VERSION "created by canmatrix"

NS_ :

BS_:

BU_: User ADM_PC_LL25 ADM_PC_BC25 ADM_PC_BP25 ADM_PC_BI25

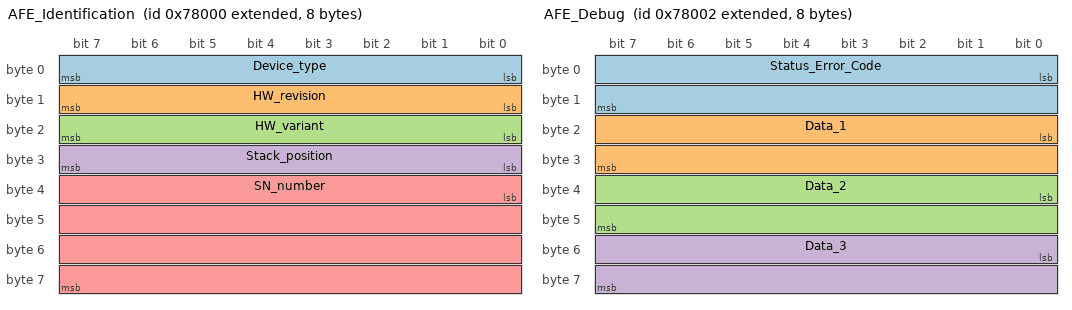
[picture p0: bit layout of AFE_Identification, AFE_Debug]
BO_ 2147975168 AFE_Identification: 8 ADM_PC_BP25
 SG_ Device_type : 0|8@1+ (1,0) [0|255] "" Vector__XXX
 SG_ HW_revision : 8|8@1+ (1,0) [0|255] "" Vector__XXX
 SG_ HW_variant : 16|8@1+ (1,0) [0|255] "" Vector__XXX
 SG_ Stack_position : 24|8@1+ (1,0) [0|255] "" Vector__XXX
 SG_ SN_number : 32|32@1+ (1,0) [0|4294967295] "" Vector__XXX

BO_ 2147975169 AFE_FwInfo: 8 ADM_PC_BP25
 SG_ FW_info_mux M : 56|8@1+ (1,0) [0|255] "" Vector__XXX
 SG_ FW_revision_0 m0 : 0|8@1+ (1,0) [0|255] "" Vector__XXX
 SG_ FW_revision_1 m0 : 8|8@1+ (1,0) [0|255] "" Vector__XXX
 SG_ FW_revision_2 m0 : 16|8@1+ (1,0) [0|255] "" Vector__XXX
 SG_ FW_revision_3 m0 : 24|8@1+ (1,0) [0|255] "" Vector__XXX
 SG_ FW_revision_4 m0 : 32|8@1+ (1,0) [0|255] "" Vector__XXX
 SG_ FW_revision_5 m0 : 40|8@1+ (1,0) [0|255] "" Vector__XXX
 SG_ FW_revision_6 m0 : 48|8@1+ (1,0) [0|255] "" Vector__XXX
 SG_ FW_revision_7 m1 : 0|8@1+ (1,0) [0|255] "" Vector__XXX
 SG_ FW_revision_8 m1 : 8|8@1+ (1,0) [0|255] "" Vector__XXX
 SG_ FW_revision_9 m1 : 16|8@1+ (1,0) [0|255] "" Vector__XXX
 SG_ FW_revision_10 m1 : 24|8@1+ (1,0) [0|255] "" Vector__XXX
 SG_ FW_revision_11 m1 : 32|8@1+ (1,0) [0|255] "" Vector__XXX
 SG_ FW_revision_12 m1 : 40|8@1+ (1,0) [0|255] "" Vector__XXX
 SG_ FW_revision_13 m1 : 48|8@1+ (1,0) [0|255] "" Vector__XXX
 SG_ FW_datecode_0 m2 : 0|8@1+ (1,0) [0|255] "" Vector__XXX
 SG_ FW_datecode_1 m2 : 8|8@1+ (1,0) [0|255] "" Vector__XXX
 SG_ FW_datecode_2 m2 : 16|8@1+ (1,0) [0|255] "" Vector__XXX
 SG_ FW_datecode_3 m2 : 24|8@1+ (1,0) [0|255] "" Vector__XXX
 SG_ FW_datecode_4 m2 : 32|8@1+ (1,0) [0|255] "" Vector__XXX
 SG_ FW_datecode_5 m2 : 40|8@1+ (1,0) [0|255] "" Vector__XXX
 SG_ FW_datecode_6 m2 : 48|8@1+ (1,0) [0|255] "" Vector__XXX
 SG_ FW_datecode_7 m3 : 0|8@1+ (1,0) [0|255] "" Vector__XXX
 SG_ FW_datecode_8 m3 : 8|8@1+ (1,0) [0|255] "" Vector__XXX
 SG_ FW_datecode_9 m3 : 16|8@1+ (1,0) [0|255] "" Vector__XXX
 SG_ FW_datecode_10 m3 : 24|8@1+ (1,0) [0|255] "" Vector__XXX
 SG_ FW_datecode_11 m3 : 32|8@1+ (1,0) [0|255] "" Vector__XXX
 SG_ FW_datecode_12 m3 : 40|8@1+ (1,0) [0|255] "" Vector__XXX
 SG_ FW_datecode_13 m3 : 48|8@1+ (1,0) [0|255] "" Vector__XXX

BO_ 2147975181 _AFE_Boot_FwInfo: 8 ADM_PC_BP25
 SG_ Boot_FW_info_mux M : 56|8@1+ (1,0) [0|255] "" Vector__XXX
 SG_ FW_revision_0 m0 : 0|8@1+ (1,0) [0|255] "" Vector__XXX
 SG_ FW_revision_1 m0 : 8|8@1+ (1,0) [0|255] "" Vector__XXX
 SG_ FW_revision_2 m0 : 16|8@1+ (1,0) [0|255] "" Vector__XXX
 SG_ FW_revision_3 m0 : 24|8@1+ (1,0) [0|255] "" Vector__XXX
 SG_ FW_revision_4 m0 : 32|8@1+ (1,0) [0|255] "" Vector__XXX
 SG_ FW_revision_5 m0 : 40|8@1+ (1,0) [0|255] "" Vector__XXX
 SG_ FW_revision_6 m0 : 48|8@1+ (1,0) [0|255] "" Vector__XXX
 SG_ FW_revision_7 m1 : 0|8@1+ (1,0) [0|255] "" Vector__XXX
 SG_ FW_revision_8 m1 : 8|8@1+ (1,0) [0|255] "" Vector__XXX
 SG_ FW_revision_9 m1 : 16|8@1+ (1,0) [0|255] "" Vector__XXX
 SG_ FW_revision_10 m1 : 24|8@1+ (1,0) [0|255] "" Vector__XXX
 SG_ FW_revision_11 m1 : 32|8@1+ (1,0) [0|255] "" Vector__XXX
 SG_ FW_revision_12 m1 : 40|8@1+ (1,0) [0|255] "" Vector__XXX
 SG_ FW_revision_13 m1 : 48|8@1+ (1,0) [0|255] "" Vector__XXX
 SG_ FW_datecode_0 m2 : 0|8@1+ (1,0) [0|255] "" Vector__XXX
 SG_ FW_datecode_1 m2 : 8|8@1+ (1,0) [0|255] "" Vector__XXX
 SG_ FW_datecode_2 m2 : 16|8@1+ (1,0) [0|255] "" Vector__XXX
 SG_ FW_datecode_3 m2 : 24|8@1+ (1,0) [0|255] "" Vector__XXX
 SG_ FW_datecode_4 m2 : 32|8@1+ (1,0) [0|255] "" Vector__XXX
 SG_ FW_datecode_5 m2 : 40|8@1+ (1,0) [0|255] "" Vector__XXX
 SG_ FW_datecode_6 m2 : 48|8@1+ (1,0) [0|255] "" Vector__XXX
 SG_ FW_datecode_7 m3 : 0|8@1+ (1,0) [0|255] "" Vector__XXX
 SG_ FW_datecode_8 m3 : 8|8@1+ (1,0) [0|255] "" Vector__XXX
 SG_ FW_datecode_9 m3 : 16|8@1+ (1,0) [0|255] "" Vector__XXX
 SG_ FW_datecode_10 m3 : 24|8@1+ (1,0) [0|255] "" Vector__XXX
 SG_ FW_datecode_11 m3 : 32|8@1+ (1,0) [0|255] "" Vector__XXX
 SG_ FW_datecode_12 m3 : 40|8@1+ (1,0) [0|255] "" Vector__XXX
 SG_ FW_datecode_13 m3 : 48|8@1+ (1,0) [0|255] "" Vector__XXX

BO_ 2147975170 AFE_Debug: 8 ADM_PC_BP25
 SG_ Status_Error_Code : 0|16@1+ (1,0) [0|65535] "" Vector__XXX
 SG_ Data_1 : 16|16@1+ (1,0) [0|65535] "" Vector__XXX
 SG_ Data_2 : 32|16@1+ (1,0) [0|65535] "" Vector__XXX
 SG_ Data_3 : 48|16@1+ (1,0) [0|65535] "" Vector__XXX

BO_ 2147975175 AFE_Status: 8 ADM_PC_BP25
 SG_ Running : 0|1@1+ (1,0) [0|1] "" Vector__XXX
 SG_ PWM : 1|1@1+ (1,0) [0|1] "" Vector__XXX
 SG_ Current_dc_loop_mode : 2|1@1+ (1,0) [0|1] "" Vector__XXX
 SG_ Current_ac_loop_mode : 3|1@1+ (1,0) [0|1] "" Vector__XXX
 SG_ Buck : 5|1@1+ (1,0) [0|1] "" Vector__XXX
 SG_ Boost : 6|1@1+ (1,0) [0|1] "" Vector__XXX
 SG_ Precharge_dc_buck_mode : 7|1@1+ (1,0) [0|1] "" Vector__XXX
 SG_ Precharge_dc_boost_mode : 8|1@1+ (1,0) [0|1] "" Vector__XXX
 SG_ Rectifier_3ph : 9|1@1+ (1,0) [0|1] "" Vector__XXX
 SG_ Stack_mode : 10|1@1+ (1,0) [0|1] "" Vector__XXX
 SG_ Master : 11|1@1+ (1,0) [0|1] "" Vector__XXX
 SG_ Slave : 12|1@1+ (1,0) [0|1] "" Vector__XXX
 SG_ Inverter_1ph : 13|1@1+ (1,0) [0|1] "" Vector__XXX
 SG_ Boost_Neutral : 14|1@1+ (1,0) [0|1] "" Vector__XXX
 SG_ Rectifier_1ph : 15|1@1+ (1,0) [0|1] "" Vector__XXX
 SG_ Inverter_3ph : 16|1@1+ (1,0) [0|1] "" Vector__XXX
 SG_ Ready : 17|1@1+ (1,0) [0|1] "" Vector__XXX
 SG_ Inverter_1ph_Sync : 18|1@1+ (1,0) [0|1] "" Vector__XXX
 SG_ Neutral : 19|1@1+ (1,0) [0|1] "" Vector__XXX
 SG_ Rectifier_1ph_Buck : 20|1@1+ (1,0) [0|1] "" Vector__XXX
 SG_ Inverter_1ph_Boost : 21|1@1+ (1,0) [0|1] "" Vector__XXX
 SG_ Rectifier_distributed : 22|1@1+ (1,0) [0|1] "" Vector__XXX
 SG_ MPPT_buck : 23|1@1+ (1,0) [0|1] "" Vector__XXX
 SG_ MPPT_boost : 24|1@1+ (1,0) [0|1] "" Vector__XXX
 SG_ Buck_2p_float : 25|1@1+ (1,0) [0|1] "" Vector__XXX
 SG_ Inverter_1ph_Distributed : 26|1@1+ (1,0) [0|1] "" Vector__XXX

BO_ 2147975174 AFE_Faults: 3 ADM_PC_BP25
 SG_ Protection_trip_internal : 0|1@1+ (1,0) [0|1] "" Vector__XXX
 SG_ Protection_trip_external : 1|1@1+ (1,0) [0|1] "" Vector__XXX
 SG_ Phase_U_overcurrent : 2|1@1+ (1,0) [0|1] "" Vector__XXX
 SG_ Phase_U_overvoltage : 3|1@1+ (1,0) [0|1] "" Vector__XXX
 SG_ Phase_U_undervoltage : 4|1@1+ (1,0) [0|1] "" Vector__XXX
 SG_ Phase_V_overvoltage : 5|1@1+ (1,0) [0|1] "" Vector__XXX
 SG_ Phase_V_undervoltage : 6|1@1+ (1,0) [0|1] "" Vector__XXX
 SG_ Phase_V_overcurrent : 7|1@1+ (1,0) [0|1] "" Vector__XXX
 SG_ Phase_W_overvoltage : 8|1@1+ (1,0) [0|1] "" Vector__XXX
 SG_ Phase_W_undervoltage : 9|1@1+ (1,0) [0|1] "" Vector__XXX
 SG_ Phase_W_overcurrent : 10|1@1+ (1,0) [0|1] "" Vector__XXX
 SG_ DC_undervoltage : 11|1@1+ (1,0) [0|1] "" Vector__XXX
 SG_ DC_overvoltage : 12|1@1+ (1,0) [0|1] "" Vector__XXX
 SG_ MOSFET_overtemperature : 13|1@1+ (1,0) [0|1] "" Vector__XXX
 SG_ Inductor_overtemperature : 14|1@1+ (1,0) [0|1] "" Vector__XXX
 SG_ Keep_Alive_not_served : 15|1@1+ (1,0) [0|1] "" Vector__XXX
 SG_ PLL_not_locked : 16|1@1+ (1,0) [0|1] "" Vector__XXX
 SG_ NFO : 20|1@1+ (1,0) [0|1] "" Vector__XXX
 SG_ Measurement_system_failure : 21|1@1+ (1,0) [0|1] "" Vector__XXX
 SG_ EEPROM_failure : 22|1@1+ (1,0) [0|1] "" Vector__XXX
 SG_ System : 23|1@1+ (1,0) [0|1] "" Vector__XXX

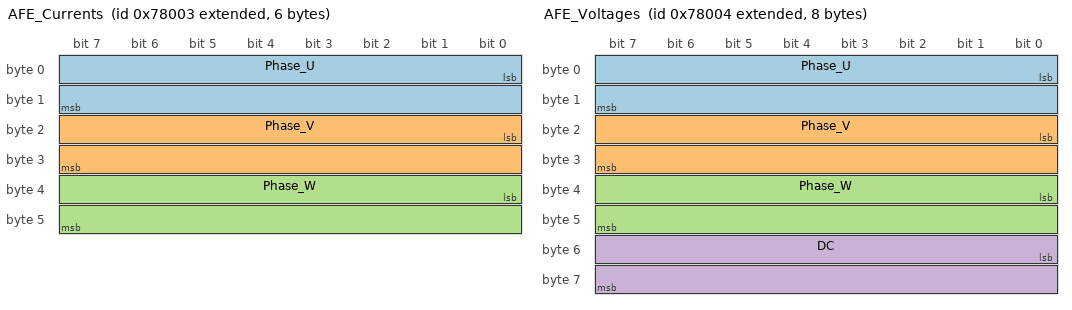
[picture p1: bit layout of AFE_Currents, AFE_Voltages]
BO_ 2147975171 AFE_Currents: 6 ADM_PC_BP25
 SG_ Phase_U : 0|16@1- (0.01,0) [-327.68|327.67] "A" Vector__XXX
 SG_ Phase_V : 16|16@1- (0.01,0) [-327.68|327.67] "A" Vector__XXX
 SG_ Phase_W : 32|16@1- (0.01,0) [-327.68|327.67] "A" Vector__XXX

BO_ 2147975184 AFE_DC_Bus_current: 2 ADM_PC_BP25
 SG_ Bus_current : 0|16@1- (0.01,0) [-327.68|327.67] "A" Vector__XXX

BO_ 2147975182 _AFE_Broadcast: 8 ADM_PC_BP25
 SG_ Diagnostics_Index M : 56|8@1+ (1,0) [0|255] "" Vector__XXX
 SG_ Phase_U m1 : 8|16@1- (0.01,0) [-327.68|327.67] "A" ADM_PC_BP25
 SG_ Phase_V m1 : 24|16@1- (0.01,0) [-327.68|327.67] "A" ADM_PC_BP25
 SG_ Phase_W m1 : 40|16@1- (0.01,0) [-327.68|327.67] "A" ADM_PC_BP25
 SG_ Stack_position : 0|5@1+ (1,0) [0|31] "" ADM_PC_BP25
 SG_ Group_ID : 5|3@1+ (1,0) [0|7] "" ADM_PC_BP25

BO_ 2147975172 AFE_Voltages: 8 ADM_PC_BP25
 SG_ Phase_U : 0|16@1- (0.1,0) [-3276.8|3276.7] "V" Vector__XXX
 SG_ Phase_V : 16|16@1- (0.1,0) [-3276.8|3276.7] "V" Vector__XXX
 SG_ Phase_W : 32|16@1- (0.1,0) [-3276.8|3276.7] "V" Vector__XXX
 SG_ DC : 48|16@1- (0.1,0) [-3276.8|3276.7] "V" Vector__XXX

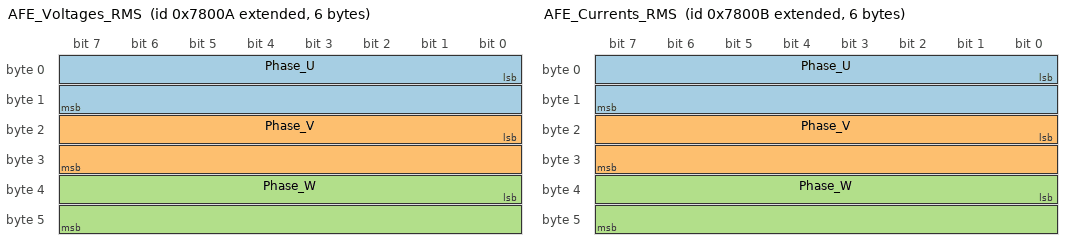
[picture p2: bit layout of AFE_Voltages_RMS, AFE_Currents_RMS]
BO_ 2147975178 AFE_Voltages_RMS: 6 ADM_PC_BP25
 SG_ Phase_U : 0|16@1+ (0.1,0) [0|6553.5] "V" Vector__XXX
 SG_ Phase_V : 16|16@1+ (0.1,0) [0|6553.5] "V" Vector__XXX
 SG_ Phase_W : 32|16@1+ (0.1,0) [0|6553.5] "V" Vector__XXX

BO_ 2147975179 AFE_Currents_RMS: 6 ADM_PC_BP25
 SG_ Phase_U : 0|16@1+ (0.01,0) [0.00|655.35] "A" Vector__XXX
 SG_ Phase_V : 16|16@1+ (0.01,0) [0.00|655.35] "A" Vector__XXX
 SG_ Phase_W : 32|16@1+ (0.01,0) [0.00|655.35] "A" Vector__XXX

BO_ 2147975180 AFE_Mains: 4 ADM_PC_BP25
 SG_ Frequency : 0|16@1+ (0.01,0) [0.00|655.35] "Hz" Vector__XXX
 SG_ Phase : 16|16@1- (0.1,0) [-3276.8|3276.7] "Deg." Vector__XXX

BO_ 2147975173 AFE_Temperatures: 4 ADM_PC_BP25
 SG_ Temp_Bridge : 0|16@1- (0.01,0) [-327.68|327.67] "°C" Vector__XXX
 SG_ Temp_Inductors : 16|16@1- (0.01,0) [-327.68|327.67] "°C" Vector__XXX

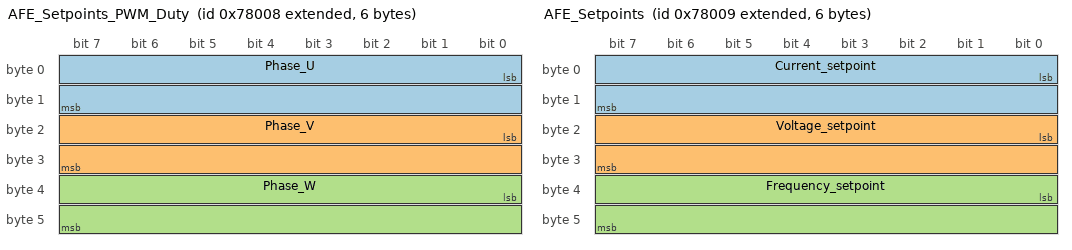
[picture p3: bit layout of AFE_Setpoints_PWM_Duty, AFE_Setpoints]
BO_ 2147975176 AFE_Setpoints_PWM_Duty: 6 ADM_PC_BP25
 SG_ Phase_U : 0|16@1+ (0.001525902,0) [0E-009|99.999987570] "%" Vector__XXX
 SG_ Phase_V : 16|16@1+ (0.001525902,0) [0E-009|99.999987570] "%" Vector__XXX
 SG_ Phase_W : 32|16@1+ (0.001525902,0) [0E-009|99.999987570] "%" Vector__XXX

BO_ 2147975177 AFE_Setpoints: 6 ADM_PC_BP25
 SG_ Current_setpoint : 0|16@1- (0.01,0) [-327.68|327.67] "A" Vector__XXX
 SG_ Voltage_setpoint : 16|16@1+ (0.1,0) [0|6553.5] "V" Vector__XXX
 SG_ Frequency_setpoint : 32|16@1+ (0.01,0) [0.00|655.35] "Hz" Vector__XXX

BO_ 2147942496 AFE_Keep_Alive: 1 User
 SG_ Keep_Alive_Enable : 0|1@1+ (1,0) [0|1] "" ADM_PC_BP25

BO_ 2147942464 AFE_Mode_Control: 8 User
 SG_ Converter_ON : 0|1@1+ (1,0) [0|1] "" ADM_PC_BP25
 SG_ PWM_ON : 1|1@1+ (1,0) [0|1] "" ADM_PC_BP25
 SG_ DC_Current_feedback_ON : 2|1@1+ (1,0) [0|1] "" ADM_PC_BP25
 SG_ AC_Current_feedback_ON : 3|1@1+ (1,0) [0|1] "" ADM_PC_BP25
 SG_ Buck_ON : 5|1@1+ (1,0) [0|1] "" ADM_PC_BP25
 SG_ Boost_ON : 6|1@1+ (1,0) [0|1] "" ADM_PC_BP25
 SG_ Rectifier_3ph_ON : 9|1@1+ (1,0) [0|1] "" ADM_PC_BP25
 SG_ Inverter_1ph_ON : 10|1@1+ (1,0) [0|1] "" ADM_PC_BP25
 SG_ Rectifier_1ph_ON : 11|1@1+ (1,0) [0|1] "" ADM_PC_BP25
 SG_ Boost_Neutral_ON : 12|1@1+ (1,0) [0|1] "" ADM_PC_BP25
 SG_ Inverter_3ph_ON : 13|1@1+ (1,0) [0|1] "" ADM_PC_BP25
 SG_ Inverter_1ph_Sync_ON : 14|1@1+ (1,0) [0|1] "" ADM_PC_BP25
 SG_ Neutral_ON : 15|1@1+ (1,0) [0|1] "" ADM_PC_BP25
 SG_ Rectifier_1ph_Buck_ON : 16|1@1+ (1,0) [0|1] "" ADM_PC_BP25
 SG_ Inverter_1ph_Boost_ON : 17|1@1+ (1,0) [0|1] "" ADM_PC_BP25
 SG_ Rectifier_Distributed_ON : 18|1@1+ (1,0) [0|1] "" ADM_PC_BP25
 SG_ MPPT_buck_ON : 19|1@1+ (1,0) [0|1] "" ADM_PC_BP25
 SG_ MPPT_boost_ON : 20|1@1+ (1,0) [0|1] "" ADM_PC_BP25
 SG_ Buck_2p_float_ON : 21|1@1+ (1,0) [0|1] "" ADM_PC_BP25
 SG_ Inverter_1ph_Distributed_ON : 22|1@1+ (1,0) [0|1] "" ADM_PC_BP25

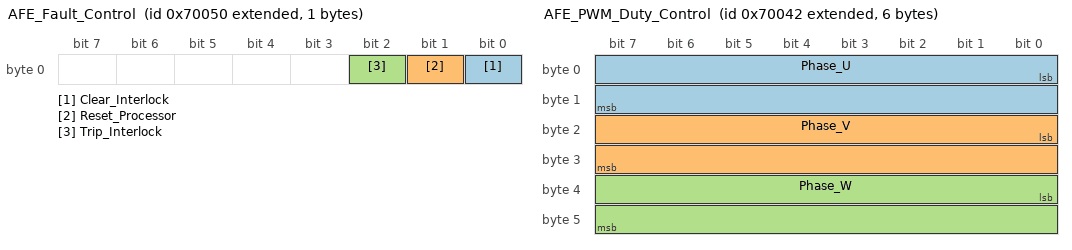
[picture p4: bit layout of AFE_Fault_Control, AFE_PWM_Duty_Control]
BO_ 2147942480 AFE_Fault_Control: 1 User
 SG_ Clear_Interlock : 0|1@1+ (1,0) [0|1] "" ADM_PC_BP25
 SG_ Reset_Processor : 1|1@1+ (1,0) [0|1] "" ADM_PC_BP25
 SG_ Trip_Interlock : 2|1@1+ (1,0) [0|1] "" ADM_PC_BP25

BO_ 2147942465 AFE_Reactive_Current_Setpoint_Co: 2 User
 SG_ Reactive_current_setpoint : 0|16@1- (0.01,0) [-150|150] "A" ADM_PC_BP25

BO_ 2147942466 AFE_PWM_Duty_Control: 6 User
 SG_ Phase_U : 0|16@1+ (0.001525902,0) [0E-009|99.999987570] "%" ADM_PC_BP25
 SG_ Phase_V : 16|16@1+ (0.001525902,0) [0E-009|99.999987570] "%" ADM_PC_BP25
 SG_ Phase_W : 32|16@1+ (0.001525902,0) [0E-009|99.999987570] "%" ADM_PC_BP25

BO_ 2147942467 AFE_Current_Setpoint_Control: 2 User
 SG_ Current_setpoint : 0|16@1- (0.01,0) [-150|150] "A" ADM_PC_BP25

BO_ 2147942468 AFE_Voltage_Setpoint_Control: 2 User
 SG_ Voltage_setpoint : 0|16@1+ (0.1,0) [0|1500] "V" ADM_PC_BP25

BO_ 2147942472 AFE_Frequency_Setpoint_Control: 2 User
 SG_ Frequency_setpoint : 0|16@1+ (0.01,0) [40|70] "Hz" ADM_PC_BP25

BO_ 2147942473 AFE_Phase_Setpoint_Control: 2 User
 SG_ Phase_setpoint : 0|16@1+ (1,0) [0|360] "deg" ADM_PC_BP25

BO_ 2147942512 AFE_Rectifier_Setpoint_Control: 8 User
 SG_ Voltage_setpoint_2 : 0|16@1+ (0.1,0) [0|1500] "V" ADM_PC_BP25
 SG_ Current_setpoint_2 : 16|16@1- (0.01,0) [-150|150] "A" ADM_PC_BP25

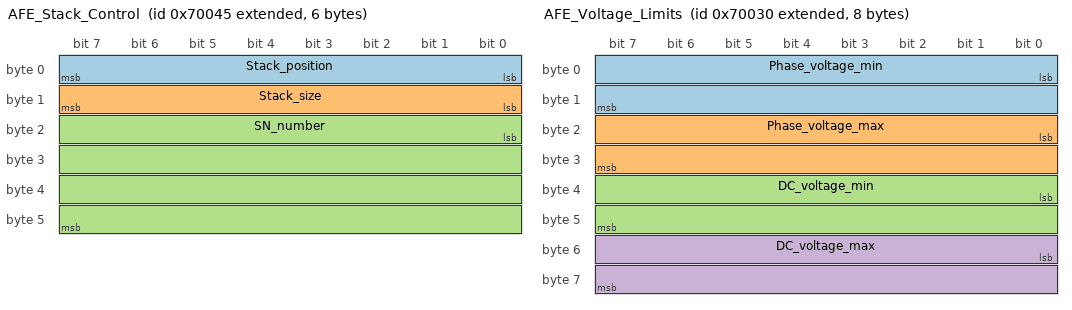
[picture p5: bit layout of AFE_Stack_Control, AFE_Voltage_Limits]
BO_ 2147942469 AFE_Stack_Control: 6 User
 SG_ Stack_position : 0|8@1+ (1,0) [0|255] "" ADM_PC_BP25
 SG_ Stack_size : 8|8@1+ (1,0) [0|255] "" ADM_PC_BP25
 SG_ SN_number : 16|32@1+ (1,0) [0|4294967295] "" ADM_PC_BP25

BO_ 2147942448 AFE_Voltage_Limits: 8 User
 SG_ Phase_voltage_min : 0|16@1- (0.1,0) [0|3276.7] "V" ADM_PC_BP25
 SG_ Phase_voltage_max : 16|16@1- (0.1,0) [-3276.8|850] "V" ADM_PC_BP25
 SG_ DC_voltage_min : 32|16@1- (0.1,0) [0|3276.7] "V" ADM_PC_BP25
 SG_ DC_voltage_max : 48|16@1- (0.1,0) [-3276.8|850] "V" ADM_PC_BP25

BO_ 2147942449 AFE_Current_Limits: 4 User
 SG_ Phase_current_min : 0|16@1- (0.01,0) [-60|60] "A" ADM_PC_BP25
 SG_ Phase_current_max : 16|16@1- (0.01,0) [-60|60] "A" ADM_PC_BP25

BO_ 2147942476 AFE_Group_Control: 1 User
 SG_ Group_ID : 0|8@1+ (1,0) [0|255] "" ADM_PC_BP25

BO_ 2147975183 AFE_Group_Info: 1 ADM_PC_BP25
 SG_ Group_ID : 0|8@1+ (1,0) [0|255] "" Vector__XXX

BO_ 2147942497 AFE_System_Flags_Control: 8 User
 SG_ Factory_mode : 0|1@1+ (1,0) [0|1] "" ADM_PC_BP25
 SG_ Silent_CAN_mode : 1|1@1+ (1,0) [0|1] "" ADM_PC_BP25

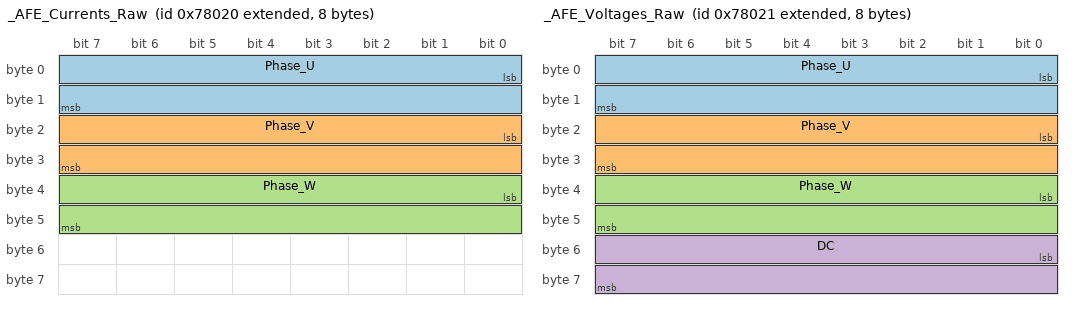
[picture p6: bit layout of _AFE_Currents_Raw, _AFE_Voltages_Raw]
BO_ 2147975200 _AFE_Currents_Raw: 8 ADM_PC_BP25
 SG_ Phase_U : 0|16@1- (1,0) [-32768|32767] "" Vector__XXX
 SG_ Phase_V : 16|16@1- (1,0) [-32768|32767] "" Vector__XXX
 SG_ Phase_W : 32|16@1- (1,0) [-32768|32767] "" Vector__XXX

BO_ 2147975201 _AFE_Voltages_Raw: 8 ADM_PC_BP25
 SG_ Phase_U : 0|16@1- (1,0) [-32768|32767] "" Vector__XXX
 SG_ Phase_V : 16|16@1- (1,0) [-32768|32767] "" Vector__XXX
 SG_ Phase_W : 32|16@1- (1,0) [-32768|32767] "" Vector__XXX
 SG_ DC : 48|16@1- (1,0) [-32768|32767] "" Vector__XXX

BO_ 2147942474 _AFE_ADC_Calibration_Mode: 1 User
 SG_ Calibration_Index M : 2|5@1+ (1,0) [0|31] "" Vector__XXX
 SG_ Current_U m1 : 0|2@1+ (1,0) [0|3] "" ADM_PC_BP25
 SG_ Current_V m2 : 0|2@1+ (1,0) [0|3] "" ADM_PC_BP25
 SG_ Current_W m3 : 0|2@1+ (1,0) [0|3] "" ADM_PC_BP25
 SG_ Voltage_U m4 : 0|2@1+ (1,0) [0|3] "" ADM_PC_BP25
 SG_ Voltage_V m5 : 0|2@1+ (1,0) [0|3] "" ADM_PC_BP25
 SG_ Voltage_W m6 : 0|2@1+ (1,0) [0|3] "" ADM_PC_BP25
 SG_ Voltage_DC m7 : 0|2@1+ (1,0) [0|3] "" ADM_PC_BP25
 SG_ start : 7|1@1+ (1,0) [0|1] "" ADM_PC_BP25

BO_ 2147942475 _AFE_ADC_Calibration_Setpoint: 3 User
 SG_ Calibration_Index M : 16|5@1+ (1,0) [0|31] "" Vector__XXX
 SG_ Current_U m1 : 0|16@1- (0.01,0) [-100|100] "A" ADM_PC_BP25
 SG_ Current_V m2 : 0|16@1- (0.01,0) [-100|100] "A" ADM_PC_BP25
 SG_ Current_W m3 : 0|16@1- (0.01,0) [-100|100] "A" ADM_PC_BP25
 SG_ Voltage_U m4 : 0|16@1+ (0.1,0) [0|1500] "V" ADM_PC_BP25
 SG_ Voltage_V m5 : 0|16@1+ (0.1,0) [0|1500] "V" ADM_PC_BP25
 SG_ Voltage_W m6 : 0|16@1+ (0.1,0) [0|1500] "V" ADM_PC_BP25
 SG_ Voltage_DC m7 : 0|16@1+ (0.1,0) [0|1500] "V" ADM_PC_BP25
 SG_ point : 21|3@1+ (1,0) [0|7] "" ADM_PC_BP25

BO_ 2147942470 _AFE_Calibration_Offset_Update: 6 User
 SG_ Calibration_Index M : 16|16@1+ (1,0) [0|65535] "" Vector__XXX
 SG_ Current_U m0 : 0|16@1- (1,0) [-32768|32767] "ADC Counts" ADM_PC_BP25
 SG_ Current_V m1 : 0|16@1- (1,0) [-32768|32767] "ADC Counts" ADM_PC_BP25
 SG_ Current_W m2 : 0|16@1- (1,0) [-32768|32767] "ADC Counts" ADM_PC_BP25
 SG_ Voltage_U m3 : 0|16@1- (1,0) [-32768|32767] "ADC Counts" ADM_PC_BP25
 SG_ Voltage_V m4 : 0|16@1- (1,0) [-32768|32767] "ADC Counts" ADM_PC_BP25
 SG_ Voltage_W m5 : 0|16@1- (1,0) [-32768|32767] "ADC Counts" ADM_PC_BP25
 SG_ Voltage_DC m6 : 0|16@1- (1,0) [-32768|32767] "ADC Counts" ADM_PC_BP25
 SG_ CRC : 32|16@1+ (1,0) [0|65535] "-" ADM_PC_BP25

BO_ 2147942471 _AFE_Calibration_Scale_Update: 6 User
 SG_ Calibration_Index M : 16|16@1+ (1,0) [0|65535] "" Vector__XXX
 SG_ Current_U m0 : 0|16@1- (0.0000152587890625,0) [-0.5000000000000000|0.4999847412109375] "scale = 1.0 + value" ADM_PC_BP25
 SG_ Current_V m1 : 0|16@1- (0.0000152587890625,0) [-0.5000000000000000|0.4999847412109375] "scale = 1.0 + value" ADM_PC_BP25
 SG_ Current_W m2 : 0|16@1- (0.0000152587890625,0) [-0.5000000000000000|0.4999847412109375] "scale = 1.0 + value" ADM_PC_BP25
 SG_ Voltage_U m3 : 0|16@1- (0.0000152587890625,0) [-0.5000000000000000|0.4999847412109375] "scale = 1.0 + value" ADM_PC_BP25
 SG_ Voltage_V m4 : 0|16@1- (0.0000152587890625,0) [-0.5000000000000000|0.4999847412109375] "scale = 1.0 + value" ADM_PC_BP25
 SG_ Voltage_W m5 : 0|16@1- (0.0000152587890625,0) [-0.5000000000000000|0.4999847412109375] "scale = 1.0 + value" ADM_PC_BP25
 SG_ Voltage_DC m6 : 0|16@1- (0.0000152587890625,0) [-0.5000000000000000|0.4999847412109375] "scale = 1.0 + value" ADM_PC_BP25
 SG_ CRC : 32|16@1+ (1,0) [0|65535] "-" ADM_PC_BP25

BO_ 2147975249 _AFE_Calibration_Adc_Scale: 6 ADM_PC_BP25
 SG_ Adc_Index M : 32|16@1+ (1,0) [0|65535] "" Vector__XXX
 SG_ Current_U m0 : 0|32@1+ (1,0) [0|4294967295] "1 / adc_bins" User
 SG_ Current_V m1 : 0|32@1+ (1,0) [0|4294967295] "1 / adc_bins" User
 SG_ Current_W m2 : 0|32@1+ (1,0) [0|4294967295] "1 / adc_bins" User
 SG_ Voltage_U m3 : 0|32@1+ (1,0) [0|4294967295] "1 / adc_bins" User
 SG_ Voltage_V m4 : 0|32@1+ (1,0) [0|4294967295] "1 / adc_bins" User
 SG_ Voltage_W m5 : 0|32@1+ (1,0) [0|4294967295] "1 / adc_bins" User
 SG_ Voltage_DC m6 : 0|32@1+ (1,0) [0|4294967295] "1 / adc_bins" User

BO_ 2147975250 _AFE_Calibration_Adc_Fs: 6 ADM_PC_BP25
 SG_ Adc_Index M : 32|16@1+ (1,0) [0|65535] "" Vector__XXX
 SG_ Current_U m0 : 0|32@1+ (1,0) [0|4294967295] "Fullscale" User
 SG_ Current_V m1 : 0|32@1+ (1,0) [0|4294967295] "Fullscale" User
 SG_ Current_W m2 : 0|32@1+ (1,0) [0|4294967295] "Fullscale" User
 SG_ Voltage_U m3 : 0|32@1+ (1,0) [0|4294967295] "Fullscale" User
 SG_ Voltage_V m4 : 0|32@1+ (1,0) [0|4294967295] "Fullscale" User
 SG_ Voltage_W m5 : 0|32@1+ (1,0) [0|4294967295] "Fullscale" User
 SG_ Voltage_DC m6 : 0|32@1+ (1,0) [0|4294967295] "Fullscale" User

BO_ 2147975251 _AFE_Calibration_Adc_Offset: 4 ADM_PC_BP25
 SG_ Adc_Index M : 16|16@1+ (1,0) [0|65535] "" Vector__XXX
 SG_ Current_U m0 : 0|16@1- (1,0) [-32768|32767] "-" User
 SG_ Current_V m1 : 0|16@1- (1,0) [-32768|32767] "-" User
 SG_ Current_W m2 : 0|16@1- (1,0) [-32768|32767] "-" User
 SG_ Voltage_U m3 : 0|16@1- (1,0) [-32768|32767] "-" User
 SG_ Voltage_V m4 : 0|16@1- (1,0) [-32768|32767] "-" User
 SG_ Voltage_W m5 : 0|16@1- (1,0) [-32768|32767] "-" User
 SG_ Voltage_DC m6 : 0|16@1- (1,0) [-32768|32767] "-" User

BO_ 2147975252 _AFE_Calibration_Adc_Gain: 4 ADM_PC_BP25
 SG_ Adc_Index M : 16|16@1+ (1,0) [0|65535] "" Vector__XXX
 SG_ Current_U m0 : 0|16@1- (1,0) [-32768|32767] "-" User
 SG_ Current_V m1 : 0|16@1- (1,0) [-32768|32767] "-" User
 SG_ Current_W m2 : 0|16@1- (1,0) [-32768|32767] "-" User
 SG_ Voltage_U m3 : 0|16@1- (1,0) [-32768|32767] "-" User
 SG_ Voltage_V m4 : 0|16@1- (1,0) [-32768|32767] "-" User
 SG_ Voltage_W m5 : 0|16@1- (1,0) [-32768|32767] "-" User
 SG_ Voltage_DC m6 : 0|16@1- (1,0) [-32768|32767] "-" User

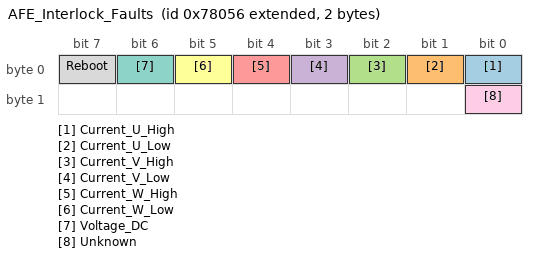
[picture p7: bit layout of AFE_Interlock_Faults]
BO_ 2147975254 AFE_Interlock_Faults: 2 ADM_PC_BP25
 SG_ Current_U_High : 0|1@1+ (1,0) [0|1] "" Vector__XXX
 SG_ Current_U_Low : 1|1@1+ (1,0) [0|1] "" Vector__XXX
 SG_ Current_V_High : 2|1@1+ (1,0) [0|1] "" Vector__XXX
 SG_ Current_V_Low : 3|1@1+ (1,0) [0|1] "" Vector__XXX
 SG_ Current_W_High : 4|1@1+ (1,0) [0|1] "" Vector__XXX
 SG_ Current_W_Low : 5|1@1+ (1,0) [0|1] "" Vector__XXX
 SG_ Voltage_DC : 6|1@1+ (1,0) [0|1] "" Vector__XXX
 SG_ Reboot : 7|1@1+ (1,0) [0|1] "" Vector__XXX
 SG_ Unknown : 8|1@1+ (1,0) [0|1] "" Vector__XXX

BO_TX_BU_ 2147942464 : User,ADM_PC_LL25,ADM_PC_BC25,ADM_PC_BI25;
BO_TX_BU_ 2147942467 : User,ADM_PC_LL25,ADM_PC_BC25,ADM_PC_BI25;
BO_TX_BU_ 2147942468 : User,ADM_PC_LL25,ADM_PC_BC25,ADM_PC_BI25;
CM_ BO_ 2147975168  "Identification of the device";
CM_ BO_ 2147975169  "Git revision of the DSP firmware";
CM_ BO_ 2147975181  "Git revision of the bootloader firmware.";
CM_ BO_ 2147975170  "Values for debugging of HW/SW problems";
CM_ BO_ 2147975175  "Status bitfield";
CM_ BO_ 2147975174  "Fault bitfield";
CM_ BO_ 2147975171  "Current of phases U, V, W";
CM_ BO_ 2147975184  "Current of of the DC Bus";
CM_ BO_ 2147975182  "All AFEs will listen to this message";
CM_ BO_ 2147975179  "RMS Current of phases U, V, W";
CM_ BO_ 2147975180  "Three-Phase mains health (frequency, phase...)";
CM_ BO_ 2147975173  "Readouts of the module temperature sensors";
CM_ BO_ 2147975176  "Setpoints";
CM_ BO_ 2147975177  "Setpoints";
CM_ BO_ 2147942496  "Keep alive ping message. ";
CM_ BO_ 2147942464  "Operation Mode control: sets the converter operation mode";
CM_ BO_ 2147942480  "Fault Control: actions to clear faults and reset the system";
CM_ BO_ 2147942465  "Reactive power setpoint control.";
CM_ BO_ 2147942466  "PWM duty cycle control";
CM_ BO_ 2147942467  "Current setpoint control";
CM_ BO_ 2147942468  "Voltage setpoint control";
CM_ BO_ 2147942472  "Frequency setpoint control";
CM_ BO_ 2147942473  "Phase setpoint control";
CM_ BO_ 2147942512  "Additional voltage and current setpoints in single-phase rectifier and inverter control modes.";
CM_ BO_ 2147942469  "PFC stack control";
CM_ BO_ 2147942448  "Set the input and output voltage limits (minimum and maximum)";
CM_ BO_ 2147942449  "Set the output current limits (mminimum and maximum)";
CM_ BO_ 2147942476  "Set the Group ID of the device";
CM_ BO_ 2147975183  "Contains the Group ID of the device";
CM_ BO_ 2147942497  "Control the system flags";
CM_ BO_ 2147975200  "Current of phases A and B";
CM_ BO_ 2147975201  "Current of phases A and B";
CM_ BO_ 2147942474  "Automatic ADC calibration.";
CM_ BO_ 2147942475  "Setpoint for automatic ADC calibration.";
CM_ BO_ 2147942470  "Update of the calibration table for offsets.";
CM_ BO_ 2147942471  "Update of the calibration table for scales.";
CM_ BO_ 2147975249  "
                Adc scale (resolution) value of readouts.
            ";
CM_ BO_ 2147975250  "
                Adc fullscale value of readouts.
            ";
CM_ BO_ 2147975251  "
                Readout of ADC calibration data (offset) from EEPROM.
            ";
CM_ BO_ 2147975252  "
                Readout of ADC calibration data (gain) from EEPROM.
            ";
CM_ BO_ 2147975254  "Fault bitfield";

CM_ SG_ 2147975168 Device_type "The device identification field, uniquely identifies the sender in the network";
CM_ SG_ 2147975168 HW_revision "The hardware revision number";
CM_ SG_ 2147975168 HW_variant "The DSP firmware revision number";
CM_ SG_ 2147975168 Stack_position "Position of the module within the stack";
CM_ SG_ 2147975168 SN_number "Unique module serial number";
CM_ SG_ 2147975169 FW_revision_0 "Character 0";
CM_ SG_ 2147975169 FW_revision_1 "Character 1";
CM_ SG_ 2147975169 FW_revision_2 "Character 2";
CM_ SG_ 2147975169 FW_revision_3 "Character 3";
CM_ SG_ 2147975169 FW_revision_4 "Character 3";
CM_ SG_ 2147975169 FW_revision_5 "Character 3";
CM_ SG_ 2147975169 FW_revision_6 "Character 3";
CM_ SG_ 2147975169 FW_revision_7 "Character 7";
CM_ SG_ 2147975169 FW_revision_8 "Character 8";
CM_ SG_ 2147975169 FW_revision_9 "Character 9";
CM_ SG_ 2147975169 FW_revision_10 "Character 10";
CM_ SG_ 2147975169 FW_revision_11 "Character 11";
CM_ SG_ 2147975169 FW_revision_12 "Character 12";
CM_ SG_ 2147975169 FW_revision_13 "Character 13";
CM_ SG_ 2147975169 FW_datecode_0 "Character 0";
CM_ SG_ 2147975169 FW_datecode_1 "Character 1";
CM_ SG_ 2147975169 FW_datecode_2 "Character 2";
CM_ SG_ 2147975169 FW_datecode_3 "Character 3";
CM_ SG_ 2147975169 FW_datecode_4 "Character 3";
CM_ SG_ 2147975169 FW_datecode_5 "Character 3";
CM_ SG_ 2147975169 FW_datecode_6 "Character 3";
CM_ SG_ 2147975169 FW_datecode_7 "Character 7";
CM_ SG_ 2147975169 FW_datecode_8 "Character 8";
CM_ SG_ 2147975169 FW_datecode_9 "Character 9";
CM_ SG_ 2147975169 FW_datecode_10 "Character 10";
CM_ SG_ 2147975169 FW_datecode_11 "Character 11";
CM_ SG_ 2147975169 FW_datecode_12 "Character 12";
CM_ SG_ 2147975169 FW_datecode_13 "Character 13";
CM_ SG_ 2147975181 FW_revision_0 "Character 0";
CM_ SG_ 2147975181 FW_revision_1 "Character 1";
CM_ SG_ 2147975181 FW_revision_2 "Character 2";
CM_ SG_ 2147975181 FW_revision_3 "Character 3";
CM_ SG_ 2147975181 FW_revision_4 "Character 3";
CM_ SG_ 2147975181 FW_revision_5 "Character 3";
CM_ SG_ 2147975181 FW_revision_6 "Character 3";
CM_ SG_ 2147975181 FW_revision_7 "Character 7";
CM_ SG_ 2147975181 FW_revision_8 "Character 8";
CM_ SG_ 2147975181 FW_revision_9 "Character 9";
CM_ SG_ 2147975181 FW_revision_10 "Character 10";
CM_ SG_ 2147975181 FW_revision_11 "Character 11";
CM_ SG_ 2147975181 FW_revision_12 "Character 12";
CM_ SG_ 2147975181 FW_revision_13 "Character 13";
CM_ SG_ 2147975181 FW_datecode_0 "Character 0";
CM_ SG_ 2147975181 FW_datecode_1 "Character 1";
CM_ SG_ 2147975181 FW_datecode_2 "Character 2";
CM_ SG_ 2147975181 FW_datecode_3 "Character 3";
CM_ SG_ 2147975181 FW_datecode_4 "Character 3";
CM_ SG_ 2147975181 FW_datecode_5 "Character 3";
CM_ SG_ 2147975181 FW_datecode_6 "Character 3";
CM_ SG_ 2147975181 FW_datecode_7 "Character 7";
CM_ SG_ 2147975181 FW_datecode_8 "Character 8";
CM_ SG_ 2147975181 FW_datecode_9 "Character 9";
CM_ SG_ 2147975181 FW_datecode_10 "Character 10";
CM_ SG_ 2147975181 FW_datecode_11 "Character 11";
CM_ SG_ 2147975181 FW_datecode_12 "Character 12";
CM_ SG_ 2147975181 FW_datecode_13 "Character 13";
CM_ SG_ 2147975170 Status_Error_Code "Main status / error code as defined in errno/errno.h";
CM_ SG_ 2147975170 Data_1 "Additional information for the error/status";
CM_ SG_ 2147975170 Data_2 "Additional information for the error/status";
CM_ SG_ 2147975170 Data_3 "Additional information for the error/status";
CM_ SG_ 2147975175 Running "Indicates if converter is running.";
CM_ SG_ 2147975175 PWM "Indicates if converter is in PWM control mode.";
CM_ SG_ 2147975175 Current_dc_loop_mode "Indicates if the current DC loop is enabled.";
CM_ SG_ 2147975175 Current_ac_loop_mode "Indicates if the current AC loop is enabled.";
CM_ SG_ 2147975175 Buck "Indicates if converter is in buck control mode.";
CM_ SG_ 2147975175 Boost "Indicates if converter is in boost control mode.";
CM_ SG_ 2147975175 Precharge_dc_buck_mode "Indicates if the precharge DC mode is enabled - buck direction.";
CM_ SG_ 2147975175 Precharge_dc_boost_mode "Indicates if the precharge DC mode is enabled - boost direction.";
CM_ SG_ 2147975175 Rectifier_3ph "Indicates if converter is in three-phase rectifier control mode.";
CM_ SG_ 2147975175 Stack_mode "Indicates if converter is operating in stack mode.";
CM_ SG_ 2147975175 Master "Indicates if converter is master in the stack.";
CM_ SG_ 2147975175 Slave "Indicates if converter is slave in the stack.";
CM_ SG_ 2147975175 Inverter_1ph "Indicates if converter is in single-phase inverter control mode.";
CM_ SG_ 2147975175 Boost_Neutral "Indicates if converter is in boost control mode with neutral generation.";
CM_ SG_ 2147975175 Rectifier_1ph "Indicates if converter is in single-phase rectifier control mode.";
CM_ SG_ 2147975175 Inverter_3ph "Indicates if converter is in three-phase inverter control mode.";
CM_ SG_ 2147975175 Ready "Indicates if converter is ready for operation.";
CM_ SG_ 2147975175 Inverter_1ph_Sync "Single-phase inverter control mode with phase synchronization.";
CM_ SG_ 2147975175 Neutral "Open-loop neutral generation.";
CM_ SG_ 2147975175 Rectifier_1ph_Buck "Single-phase rectifier with buck on one leg.";
CM_ SG_ 2147975175 Inverter_1ph_Boost "Single-phase inverter with boost on one leg.";
CM_ SG_ 2147975175 Rectifier_distributed "Not available at the moment";
CM_ SG_ 2147975175 MPPT_buck "Not available at the moment";
CM_ SG_ 2147975175 MPPT_boost "Not available at the moment";
CM_ SG_ 2147975175 Buck_2p_float "Buck in phases L1 and L2. Phase L3 is left floating (high impedance)";
CM_ SG_ 2147975175 Inverter_1ph_Distributed "Single-phase inverter mode  distributed";
CM_ SG_ 2147975174 Protection_trip_internal "This flagg is asserted if the interlock is open due to an internal fault condition (self-protection)";
CM_ SG_ 2147975174 Protection_trip_external "This flag is asserted if the interlock is open due to an external condition received in the module.";
CM_ SG_ 2147975174 Phase_U_overcurrent "Indicates an overcurrent event on Phase U. The overcurrent event is triggered when the measured phase current is over the programmed current limit.";
CM_ SG_ 2147975174 Phase_U_overvoltage "Indicates an overvoltage event on Phase U. The overvoltage event is triggered when the measured phase voltage is over the programmed voltage limit.";
CM_ SG_ 2147975174 Phase_U_undervoltage "Indicates an undervoltage event on Phase U. The overvoltage event is triggered when the measured phase voltage is over the programmed voltage limit.";
CM_ SG_ 2147975174 Phase_V_overvoltage "Indicates an overvoltage event on Phase V. The overvoltage event is triggered when the measured phase voltage is over the programmed voltage limit.";
CM_ SG_ 2147975174 Phase_V_undervoltage "Indicates an undervoltage event on Phase U. The overvoltage event is triggered when the measured phase voltage is over the programmed voltage limit.";
CM_ SG_ 2147975174 Phase_V_overcurrent "Indicates an overcurrent event on Phase U. The overcurrent event is triggered when the measured phase current is over the programmed current limit.";
CM_ SG_ 2147975174 Phase_W_overvoltage "Indicates an overvoltage event on Phase U. The overvoltage event is triggered when the measured phase voltage is over the programmed voltage limit.";
CM_ SG_ 2147975174 Phase_W_undervoltage "Indicates an undervoltage event on Phase U. The overvoltage event is triggered when the measured phase voltage is over the programmed voltage limit.";
CM_ SG_ 2147975174 Phase_W_overcurrent "Indicates an overcurrent event on Phase U. The overcurrent event is triggered when the measured phase current is over the programmed current limit.";
CM_ SG_ 2147975174 DC_undervoltage "DC bus undervoltage condition. The undervoltage condition is asserted when the measured dc bus voltage is under the programmed voltage limit.";
CM_ SG_ 2147975174 DC_overvoltage "DC bus overvoltage condition. The overvoltage condition is asserted when the measured dc bus voltage is over the programmed voltage limit.";
CM_ SG_ 2147975174 MOSFET_overtemperature "This flag is asserted when the temperature of the MOSFET block is too high.";
CM_ SG_ 2147975174 Inductor_overtemperature "This flag is asserted when the temperature of the inductor block is too high.";
CM_ SG_ 2147975174 Keep_Alive_not_served "The Keep Alive feature is enabled but it was not served with the periodic message.";
CM_ SG_ 2147975174 PLL_not_locked "Flag asserted when in rectifier modes, the PLL went out of lock condition";
CM_ SG_ 2147975174 Measurement_system_failure "The voltages/currents measurement system is malfunctionning, and readouts are not guaranteed to be accurate.";
CM_ SG_ 2147975174 EEPROM_failure "The configuration EEPROM failed to load or save the module configuration.";
CM_ SG_ 2147975171 Phase_U "Phase current is the MOSFET loop current, in the branch U of the converter.";
CM_ SG_ 2147975171 Phase_V "Phase current is the MOSFET loop current, in the branch V of the converter.";
CM_ SG_ 2147975171 Phase_W "Phase current is the MOSFET loop current, in the branch W of the converter.";
CM_ SG_ 2147975184 Bus_current "DC Bus current is possitive when current goes from input to output";
CM_ SG_ 2147975182 Phase_U "Phase current is the MOSFET loop current, in the branch U of the converter.";
CM_ SG_ 2147975182 Phase_V "Phase current is the MOSFET loop current, in the branch V of the converter.";
CM_ SG_ 2147975182 Phase_W "Phase current is the MOSFET loop current, in the branch W of the converter.";
CM_ SG_ 2147975182 Stack_position "Sender Stack position";
CM_ SG_ 2147975182 Group_ID "Sender Group ID";
CM_ SG_ 2147975179 Phase_U "RMS Phase current is the MOSFET loop current, in the branch U of the converter.";
CM_ SG_ 2147975179 Phase_V "RMS Phase current is the MOSFET loop current, in the branch V of the converter.";
CM_ SG_ 2147975179 Phase_W "RMS Phase current is the MOSFET loop current, in the branch W of the converter.";
CM_ SG_ 2147975180 Frequency "Frequency of Three-Phase system";
CM_ SG_ 2147975180 Phase "Phase of Three-Phase system";
CM_ SG_ 2147975173 Temp_Bridge "Temperature of the MOSFET block";
CM_ SG_ 2147975173 Temp_Inductors "Temperature of the inductors";
CM_ SG_ 2147975176 Phase_U "The actual PWM duty cycle setpoint";
CM_ SG_ 2147975176 Phase_V "The actual PWM duty cycle setpoint";
CM_ SG_ 2147975176 Phase_W "The actual PWM duty cycle setpoint";
CM_ SG_ 2147975177 Current_setpoint "The actual current setpoint";
CM_ SG_ 2147975177 Voltage_setpoint "The actual voltage setpoint";
CM_ SG_ 2147975177 Frequency_setpoint "The actual frequency setpoint";
CM_ SG_ 2147942496 Keep_Alive_Enable "If set to 1, module will expect to receive this message every second repeatedly, or it will stop operation";
CM_ SG_ 2147942464 Converter_ON "Enable the converter.";
CM_ SG_ 2147942464 PWM_ON "Enable the PWM control mode.";
CM_ SG_ 2147942464 DC_Current_feedback_ON "Enable the DC current loop";
CM_ SG_ 2147942464 AC_Current_feedback_ON "Enable the AC current loop";
CM_ SG_ 2147942464 Buck_ON "Enable the buck control mode.";
CM_ SG_ 2147942464 Boost_ON "Enable the boost control mode.";
CM_ SG_ 2147942464 Rectifier_3ph_ON "Enable the three-phase rectifier control mode.";
CM_ SG_ 2147942464 Inverter_1ph_ON "Enable the single-phase inverter control mode.";
CM_ SG_ 2147942464 Rectifier_1ph_ON "Enable the single-phase rectifier control mode.";
CM_ SG_ 2147942464 Boost_Neutral_ON "Enable the boost control mode with neutral generation.";
CM_ SG_ 2147942464 Inverter_3ph_ON "Enable the three-phase inverter control mode.";
CM_ SG_ 2147942464 Inverter_1ph_Sync_ON "Single-phase inverter control mode with phase synchronization.";
CM_ SG_ 2147942464 Neutral_ON "Open-loop neutral generation.";
CM_ SG_ 2147942464 Rectifier_1ph_Buck_ON "Single-phase rectifier with buck on one leg.";
CM_ SG_ 2147942464 Inverter_1ph_Boost_ON "Single-phase inverter with boost on one leg.";
CM_ SG_ 2147942464 Rectifier_Distributed_ON "Single-phase (floating) distributed rectifier";
CM_ SG_ 2147942464 MPPT_buck_ON "MPPT buck";
CM_ SG_ 2147942464 MPPT_boost_ON "MPPT boost";
CM_ SG_ 2147942464 Buck_2p_float_ON "Boost on L1 and L2. Floating L3 (high-impedance)";
CM_ SG_ 2147942464 Inverter_1ph_Distributed_ON "Single-phase inverter mode distributed";
CM_ SG_ 2147942480 Clear_Interlock "Clears the converter interlock";
CM_ SG_ 2147942480 Reset_Processor "Reset the converter DSP";
CM_ SG_ 2147942480 Trip_Interlock "Trip the inetrnal Interlock";
CM_ SG_ 2147942465 Reactive_current_setpoint "This defines reactive current setpoint for 3-phase rectifier mode";
CM_ SG_ 2147942466 Phase_U "The actual PWM duty cycle setpoint";
CM_ SG_ 2147942466 Phase_V "The actual PWM duty cycle setpoint";
CM_ SG_ 2147942466 Phase_W "The actual PWM duty cycle setpoint";
CM_ SG_ 2147942467 Current_setpoint "Sets the output current setpoint. Active only when the current loop is enabled";
CM_ SG_ 2147942468 Voltage_setpoint "Sets the output voltage setpoint. Active only when the voltage loop is enabled";
CM_ SG_ 2147942472 Frequency_setpoint "Sets the frequency for single-phase and three-phase generator modes.";
CM_ SG_ 2147942473 Phase_setpoint "Sets the phase for inverter control modes.";
CM_ SG_ 2147942469 Stack_position "The converter position within the stack";
CM_ SG_ 2147942469 Stack_size "How many PFC converters are in stack in total";
CM_ SG_ 2147942469 SN_number "Unique module serial number";
CM_ SG_ 2147942448 Phase_voltage_min "Minimum tolerated phase voltage";
CM_ SG_ 2147942448 Phase_voltage_max "Maximum allowable phase voltage";
CM_ SG_ 2147942448 DC_voltage_min "Minimum allowable dc voltage";
CM_ SG_ 2147942448 DC_voltage_max "Maximum allowable dc voltage";
CM_ SG_ 2147942449 Phase_current_min "Minimum allowable output current";
CM_ SG_ 2147942449 Phase_current_max "Maximum allowable output current";
CM_ SG_ 2147942476 Group_ID "Desired group ID for the device";
CM_ SG_ 2147975183 Group_ID "Group ID of the device";
CM_ SG_ 2147942497 Factory_mode "Customers MUST NOT USE this bit. If set to 1, module will enter in factory mode. ";
CM_ SG_ 2147942497 Silent_CAN_mode "Customers MUST NOT USE this bit. If set to 1, module will enter in factory mode. ";
CM_ SG_ 2147942474 start "Start automatic calibration. Multiplexer index must be 0!";
CM_ SG_ 2147942475 point "Calibration point index.";
CM_ SG_ 2147942470 CRC "Checksum of bytes 0 to 3, CRC-CCITT, corresponding to qChecksum (www.qt.io)";
CM_ SG_ 2147942471 CRC "Checksum of bytes 0 to 3, CRC-CCITT, corresponding to qChecksum (www.qt.io)";
CM_ SG_ 2147975254 Current_U_High "This flag is set if a hight current on U tripped the internal interlock";
CM_ SG_ 2147975254 Current_U_Low "This flag is set if a low current on U tripped the internal interlock";
CM_ SG_ 2147975254 Current_V_High "This flag is set if a hight current on V tripped the internal interlock";
CM_ SG_ 2147975254 Current_V_Low "This flag is set if a low current on V tripped the internal interlock";
CM_ SG_ 2147975254 Current_W_High "This flag is set if a hight current on W tripped the internal interlock";
CM_ SG_ 2147975254 Current_W_Low "This flag is set if a low current on W tripped the internal interlock";
CM_ SG_ 2147975254 Voltage_DC "This flag is set if a voltage on DC tripped the internal interlock";
CM_ SG_ 2147975254 Reboot "This flag is set if a reboot tripped the internal interlock";
CM_ SG_ 2147975254 Unknown "This flag the reason for the internal interlock is unknown";

BA_DEF_ BO_ "SystemMessageLongSymbol" STRING;

BA_ "SystemMessageLongSymbol" BO_ 2147942465 "AFE_Reactive_Current_Setpoint_Control";

VAL_ 2147975168 Device_type 7 "AFE";
VAL_ 2147975174 Protection_trip_internal 1 "fault";
VAL_ 2147975174 Protection_trip_external 1 "fault";
VAL_ 2147975174 Phase_U_overcurrent 1 "fault";
VAL_ 2147975174 Phase_U_overvoltage 1 "fault";
VAL_ 2147975174 Phase_U_undervoltage 1 "fault";
VAL_ 2147975174 Phase_V_overvoltage 1 "fault";
VAL_ 2147975174 Phase_V_undervoltage 1 "fault";
VAL_ 2147975174 Phase_V_overcurrent 1 "fault";
VAL_ 2147975174 Phase_W_overvoltage 1 "fault";
VAL_ 2147975174 Phase_W_undervoltage 1 "fault";
VAL_ 2147975174 Phase_W_overcurrent 1 "fault";
VAL_ 2147975174 DC_undervoltage 1 "fault";
VAL_ 2147975174 DC_overvoltage 1 "fault";
VAL_ 2147975174 MOSFET_overtemperature 1 "fault";
VAL_ 2147975174 Inductor_overtemperature 1 "fault";
VAL_ 2147975174 Keep_Alive_not_served 1 "fault";
VAL_ 2147975174 PLL_not_locked 1 "fault";
VAL_ 2147975174 NFO 1 "fault";
VAL_ 2147975174 Measurement_system_failure 1 "fault";
VAL_ 2147975174 EEPROM_failure 1 "fault";
VAL_ 2147975174 System 1 "fault";
VAL_ 2147975254 Current_U_High 1 "fault";
VAL_ 2147975254 Current_U_Low 1 "fault";
VAL_ 2147975254 Current_V_High 1 "fault";
VAL_ 2147975254 Current_V_Low 1 "fault";
VAL_ 2147975254 Current_W_High 1 "fault";
VAL_ 2147975254 Current_W_Low 1 "fault";
VAL_ 2147975254 Voltage_DC 1 "fault";
VAL_ 2147975254 Reboot 1 "fault";
VAL_ 2147975254 Unknown 1 "fault";
SIG_VALTYPE_ 2147975249 Current_U : 1;
SIG_VALTYPE_ 2147975249 Current_V : 1;
SIG_VALTYPE_ 2147975249 Current_W : 1;
SIG_VALTYPE_ 2147975249 Voltage_U : 1;
SIG_VALTYPE_ 2147975249 Voltage_V : 1;
SIG_VALTYPE_ 2147975249 Voltage_W : 1;
SIG_VALTYPE_ 2147975249 Voltage_DC : 1;
SIG_VALTYPE_ 2147975250 Current_U : 1;
SIG_VALTYPE_ 2147975250 Current_V : 1;
SIG_VALTYPE_ 2147975250 Current_W : 1;
SIG_VALTYPE_ 2147975250 Voltage_U : 1;
SIG_VALTYPE_ 2147975250 Voltage_V : 1;
SIG_VALTYPE_ 2147975250 Voltage_W : 1;
SIG_VALTYPE_ 2147975250 Voltage_DC : 1;
